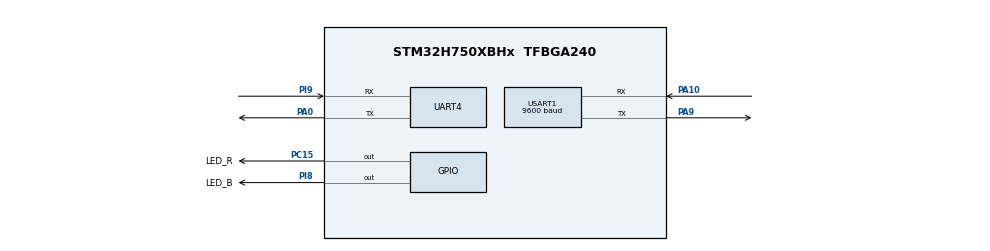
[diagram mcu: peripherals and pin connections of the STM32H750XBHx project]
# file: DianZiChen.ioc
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Mcu.Family=STM32H7
Mcu.Name=STM32H750XBHx
Mcu.Package=TFBGA240
NVIC.PriorityGroup=NVIC_PRIORITYGROUP_4
PA0.Mode=Asynchronous
PA0.Signal=UART4_TX
PA10.Mode=Asynchronous
PA10.Signal=USART1_RX
PA9.Mode=Asynchronous
PA9.Signal=USART1_TX
PC15-OSC32_OUT\ (OSC32_OUT).GPIO_Label=LED_R
PC15-OSC32_OUT\ (OSC32_OUT).GPIO_ModeDefaultOutputPP=GPIO_MODE_OUTPUT_PP
PC15-OSC32_OUT\ (OSC32_OUT).GPIO_PuPd=GPIO_PULLUP
PC15-OSC32_OUT\ (OSC32_OUT).PinState=GPIO_PIN_SET
PC15-OSC32_OUT\ (OSC32_OUT).Signal=GPIO_Output
PH0-OSC_IN\ (PH0).Mode=HSE-External-Oscillator
PH0-OSC_IN\ (PH0).Signal=RCC_OSC_IN
PH1-OSC_OUT\ (PH1).Mode=HSE-External-Oscillator
PH1-OSC_OUT\ (PH1).Signal=RCC_OSC_OUT
PI8.GPIO_Label=LED_B
PI8.GPIO_ModeDefaultOutputPP=GPIO_MODE_OUTPUT_PP
PI8.GPIO_PuPd=GPIO_PULLUP
PI8.PinState=GPIO_PIN_SET
PI8.Signal=GPIO_Output
PI9.Mode=Asynchronous
PI9.Signal=UART4_RX
ProjectManager.HeapSize=0x200
ProjectManager.StackSize=0x400
ProjectManager.TargetToolchain=STM32CubeIDE
RCC.ADCFreq_Value=50390625
RCC.APB1Freq_Value=120000000
RCC.APB2Freq_Value=120000000
RCC.APB3Freq_Value=120000000
RCC.APB4Freq_Value=120000000
RCC.CortexFreq_Value=480000000
RCC.D1PPRE=RCC_APB3_DIV2
RCC.D2PPRE1=RCC_APB1_DIV2
RCC.D2PPRE2=RCC_APB2_DIV2
RCC.D3PPRE=RCC_APB4_DIV2
RCC.DIVM1=5
RCC.DIVN1=192
RCC.HCLKFreq_Value=240000000
RCC.HPRE=RCC_HCLK_DIV2
RCC.PLLSourceVirtual=RCC_PLLSOURCE_HSE
RCC.SYSCLKFreq_VALUE=480000000
RCC.SYSCLKSource=RCC_SYSCLKSOURCE_PLLCLK
RCC.USBFreq_Value=480000000
USART1.BaudRate=9600
USART1.VirtualMode-Asynchronous=VM_ASYNC
board=custom

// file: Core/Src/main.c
/* USER CODE BEGIN Header */
/**
  ******************************************************************************
  * @file           : main.c
  * @brief          : Main program body
  ******************************************************************************
  * @attention
  *
  * <h2><center>&copy; Copyright (c) 2021 STMicroelectronics.
  * All rights reserved.</center></h2>
  *
  * This software component is licensed by ST under BSD 3-Clause license,
  * the "License"; You may not use this file except in compliance with the
  * License. You may obtain a copy of the License at:
  *                        opensource.org/licenses/BSD-3-Clause
  *
  ******************************************************************************
  */
/* USER CODE END Header */
#include "main.h"

/* USER CODE BEGIN Includes */

#include "stdio.h"
#include "bsp_delay.h"
#include "bsp_hx711.h"
#include "bsp_dubug.h"
#include "bsp_led.h"
/* USER CODE END Includes */

UART_HandleTypeDef huart4;
UART_HandleTypeDef huart1;

void SystemClock_Config(void);
static void MX_GPIO_Init(void);
static void MX_UART4_Init(void);
static void MX_USART1_UART_Init(void);

int main(void)
{

  /* MCU Configuration--------------------------------------------------------*/

  /* Reset of all peripherals, Initializes the Flash interface and the Systick. */
  HAL_Init();

  /* Configure the system clock */
  SystemClock_Config();

  /* USER CODE BEGIN SysInit */
  bsp_DelayInit();
  bsp_Hx711Init();
  /* USER CODE END SysInit */

  /* Initialize all configured peripherals */
  MX_GPIO_Init();
  MX_UART4_Init();
  MX_USART1_UART_Init();
  /* USER CODE BEGIN 2 */
 // bsp_DubugInit();
  /* USER CODE END 2 */

  /* Infinite loop */
  /* USER CODE BEGIN WHILE */
  bsp_Hx711GetMaopi();
  bsp_DelayMs(2000);
  bsp_Hx711GetMaopi();
  while (1)
  {
      bsp_Hx711GetWeight();
      bsp_DBPrintf("称重重量为：%d g\r\n\n",Weight_Shiwu); //调试串口打印
      bsp_U1Printf("t0.txt=\"%dg\"\xff\xff\xff",Weight_Shiwu);//向串口屏发送数据
      bsp_DelayMs(200);
    /* USER CODE END WHILE */

  }
}

void SystemClock_Config(void)
{
  RCC_OscInitTypeDef RCC_OscInitStruct = {0};
  RCC_ClkInitTypeDef RCC_ClkInitStruct = {0};
  RCC_PeriphCLKInitTypeDef PeriphClkInitStruct = {0};

  /** Supply configuration update enable
  */
  HAL_PWREx_ConfigSupply(PWR_LDO_SUPPLY);
  /** Configure the main internal regulator output voltage
  */
  __HAL_PWR_VOLTAGESCALING_CONFIG(PWR_REGULATOR_VOLTAGE_SCALE0);

  while(!__HAL_PWR_GET_FLAG(PWR_FLAG_VOSRDY)) {}
  /** Initializes the RCC Oscillators according to the specified parameters
  * in the RCC_OscInitTypeDef structure.
  */
  RCC_OscInitStruct.OscillatorType = RCC_OSCILLATORTYPE_HSE;
  RCC_OscInitStruct.HSEState = RCC_HSE_ON;
  RCC_OscInitStruct.PLL.PLLState = RCC_PLL_ON;
  RCC_OscInitStruct.PLL.PLLSource = RCC_PLLSOURCE_HSE;
  RCC_OscInitStruct.PLL.PLLM = 5;
  RCC_OscInitStruct.PLL.PLLN = 192;
  RCC_OscInitStruct.PLL.PLLP = 2;
  RCC_OscInitStruct.PLL.PLLQ = 2;
  RCC_OscInitStruct.PLL.PLLR = 2;
  RCC_OscInitStruct.PLL.PLLRGE = RCC_PLL1VCIRANGE_2;
  RCC_OscInitStruct.PLL.PLLVCOSEL = RCC_PLL1VCOWIDE;
  RCC_OscInitStruct.PLL.PLLFRACN = 0;
  if (HAL_RCC_OscConfig(&RCC_OscInitStruct) != HAL_OK)
  {
    Error_Handler();
  }
  /** Initializes the CPU, AHB and APB buses clocks
  */
  RCC_ClkInitStruct.ClockType = RCC_CLOCKTYPE_HCLK|RCC_CLOCKTYPE_SYSCLK
                              |RCC_CLOCKTYPE_PCLK1|RCC_CLOCKTYPE_PCLK2
                              |RCC_CLOCKTYPE_D3PCLK1|RCC_CLOCKTYPE_D1PCLK1;
  RCC_ClkInitStruct.SYSCLKSource = RCC_SYSCLKSOURCE_PLLCLK;
  RCC_ClkInitStruct.SYSCLKDivider = RCC_SYSCLK_DIV1;
  RCC_ClkInitStruct.AHBCLKDivider = RCC_HCLK_DIV2;
  RCC_ClkInitStruct.APB3CLKDivider = RCC_APB3_DIV2;
  RCC_ClkInitStruct.APB1CLKDivider = RCC_APB1_DIV2;
  RCC_ClkInitStruct.APB2CLKDivider = RCC_APB2_DIV2;
  RCC_ClkInitStruct.APB4CLKDivider = RCC_APB4_DIV2;

  if (HAL_RCC_ClockConfig(&RCC_ClkInitStruct, FLASH_LATENCY_4) != HAL_OK)
  {
    Error_Handler();
  }
  PeriphClkInitStruct.PeriphClockSelection = RCC_PERIPHCLK_UART4|RCC_PERIPHCLK_USART1;
  PeriphClkInitStruct.Usart234578ClockSelection = RCC_USART234578CLKSOURCE_D2PCLK1;
  PeriphClkInitStruct.Usart16ClockSelection = RCC_USART16CLKSOURCE_D2PCLK2;
  if (HAL_RCCEx_PeriphCLKConfig(&PeriphClkInitStruct) != HAL_OK)
  {
    Error_Handler();
  }
}

static void MX_UART4_Init(void)
{

  huart4.Instance = UART4;
  huart4.Init.BaudRate = 115200;
  huart4.Init.WordLength = UART_WORDLENGTH_8B;
  huart4.Init.StopBits = UART_STOPBITS_1;
  huart4.Init.Parity = UART_PARITY_NONE;
  huart4.Init.Mode = UART_MODE_TX_RX;
  huart4.Init.HwFlowCtl = UART_HWCONTROL_NONE;
  huart4.Init.OverSampling = UART_OVERSAMPLING_16;
  huart4.Init.OneBitSampling = UART_ONE_BIT_SAMPLE_DISABLE;
  huart4.Init.ClockPrescaler = UART_PRESCALER_DIV1;
  huart4.AdvancedInit.AdvFeatureInit = UART_ADVFEATURE_NO_INIT;
  if (HAL_UART_Init(&huart4) != HAL_OK)
  {
    Error_Handler();
  }
  if (HAL_UARTEx_SetTxFifoThreshold(&huart4, UART_TXFIFO_THRESHOLD_1_8) != HAL_OK)
  {
    Error_Handler();
  }
  if (HAL_UARTEx_SetRxFifoThreshold(&huart4, UART_RXFIFO_THRESHOLD_1_8) != HAL_OK)
  {
    Error_Handler();
  }
  if (HAL_UARTEx_DisableFifoMode(&huart4) != HAL_OK)
  {
    Error_Handler();
  }

}

static void MX_USART1_UART_Init(void)
{

  huart1.Instance = USART1;
  huart1.Init.BaudRate = 9600;
  huart1.Init.WordLength = UART_WORDLENGTH_8B;
  huart1.Init.StopBits = UART_STOPBITS_1;
  huart1.Init.Parity = UART_PARITY_NONE;
  huart1.Init.Mode = UART_MODE_TX_RX;
  huart1.Init.HwFlowCtl = UART_HWCONTROL_NONE;
  huart1.Init.OverSampling = UART_OVERSAMPLING_16;
  huart1.Init.OneBitSampling = UART_ONE_BIT_SAMPLE_DISABLE;
  huart1.Init.ClockPrescaler = UART_PRESCALER_DIV1;
  huart1.AdvancedInit.AdvFeatureInit = UART_ADVFEATURE_NO_INIT;
  if (HAL_UART_Init(&huart1) != HAL_OK)
  {
    Error_Handler();
  }
  if (HAL_UARTEx_SetTxFifoThreshold(&huart1, UART_TXFIFO_THRESHOLD_1_8) != HAL_OK)
  {
    Error_Handler();
  }
  if (HAL_UARTEx_SetRxFifoThreshold(&huart1, UART_RXFIFO_THRESHOLD_1_8) != HAL_OK)
  {
    Error_Handler();
  }
  if (HAL_UARTEx_DisableFifoMode(&huart1) != HAL_OK)
  {
    Error_Handler();
  }

}

static void MX_GPIO_Init(void)
{
  GPIO_InitTypeDef GPIO_InitStruct = {0};

  /* GPIO Ports Clock Enable */
  __HAL_RCC_GPIOC_CLK_ENABLE();
  __HAL_RCC_GPIOA_CLK_ENABLE();
  __HAL_RCC_GPIOI_CLK_ENABLE();
  __HAL_RCC_GPIOH_CLK_ENABLE();

  /*Configure GPIO pin Output Level */
  HAL_GPIO_WritePin(LED_R_GPIO_Port, LED_R_Pin, GPIO_PIN_SET);

  /*Configure GPIO pin Output Level */
  HAL_GPIO_WritePin(LED_B_GPIO_Port, LED_B_Pin, GPIO_PIN_SET);

  /*Configure GPIO pin : LED_R_Pin */
  GPIO_InitStruct.Pin = LED_R_Pin;
  GPIO_InitStruct.Mode = GPIO_MODE_OUTPUT_PP;
  GPIO_InitStruct.Pull = GPIO_PULLUP;
  GPIO_InitStruct.Speed = GPIO_SPEED_FREQ_LOW;
  HAL_GPIO_Init(LED_R_GPIO_Port, &GPIO_InitStruct);

  /*Configure GPIO pin : LED_B_Pin */
  GPIO_InitStruct.Pin = LED_B_Pin;
  GPIO_InitStruct.Mode = GPIO_MODE_OUTPUT_PP;
  GPIO_InitStruct.Pull = GPIO_PULLUP;
  GPIO_InitStruct.Speed = GPIO_SPEED_FREQ_LOW;
  HAL_GPIO_Init(LED_B_GPIO_Port, &GPIO_InitStruct);

}

void Error_Handler(void)
{
  __disable_irq();
  while (1)
  {
  }
}

/************************ (C) COPYRIGHT STMicroelectronics *****END OF FILE****/
